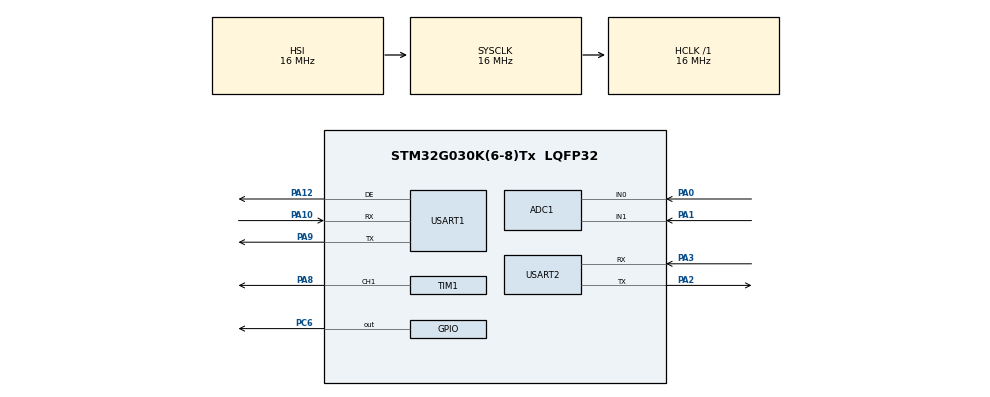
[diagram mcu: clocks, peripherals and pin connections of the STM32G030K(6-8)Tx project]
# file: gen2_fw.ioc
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ADC1.Channel-0\#ChannelRegularConversion=ADC_CHANNEL_0
ADC1.NbrOfConversionFlag=1
ADC1.Rank-0\#ChannelRegularConversion=1
ADC1.SamplingTime-0\#ChannelRegularConversion=ADC_SAMPLINGTIME_COMMON_1
ADC1.SelectedChannel=ADC_CHANNEL_0|ADC_CHANNEL_1
ADC1.master=1
Mcu.Family=STM32G0
Mcu.Name=STM32G030K(6-8)Tx
Mcu.Package=LQFP32
PA0.Mode=IN0
PA0.Signal=ADC1_IN0
PA1.Mode=IN1
PA1.Signal=ADC1_IN1
PA10.Mode=Asynchronous
PA10.Signal=USART1_RX
PA12\ [PA10].Mode=Hardware Flow Control (RS485)
PA12\ [PA10].Signal=USART1_DE
PA13.Mode=Serial_Wire
PA13.Signal=SYS_SWDIO
PA14-BOOT0.Mode=Serial_Wire
PA14-BOOT0.Signal=SYS_SWCLK
PA2.Mode=Asynchronous
PA2.Signal=USART2_TX
PA3.Mode=Asynchronous
PA3.Signal=USART2_RX
PA8.Signal=S_TIM1_CH1
PA9.Mode=Asynchronous
PA9.Signal=USART1_TX
PC14-OSC32_IN\ (PC14).Mode=HSE-External-Clock-Source
PC14-OSC32_IN\ (PC14).Signal=RCC_OSC_IN
PC6.Signal=GPIO_Output
ProjectManager.HeapSize=0x200
ProjectManager.StackSize=0x400
ProjectManager.TargetToolchain=CMake
RCC.AHBFreq_Value=16000000
RCC.CortexFreq_Value=16000000
RCC.EXTERNAL_CLOCK_VALUE=12288000
RCC.HCLKFreq_Value=16000000
RCC.HSE_VALUE=8000000
RCC.HSI_VALUE=16000000
RCC.LSE_VALUE=32768
RCC.SYSCLKFreq_VALUE=16000000
RCC.VCOOutputFreq_Value=128000000
SH.S_TIM1_CH1.0=TIM1_CH1,Output Compare1 CH1
TIM1.Channel-Output\ Compare1\ CH1=TIM_CHANNEL_1
USART1.VirtualMode-Asynchronous=VM_ASYNC
USART1.VirtualMode-Hardware\ Flow\ Control\ (RS485)=VM_ASYNC
USART2.VirtualMode-Asynchronous=VM_ASYNC
board=custom

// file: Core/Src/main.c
/* USER CODE BEGIN Header */
/**
 ******************************************************************************
 * @file           : main.c
 * @brief          : Main program body
 ******************************************************************************
 * @attention
 *
 * Copyright (c) 2026 STMicroelectronics.
 * All rights reserved.
 *
 * This software is licensed under terms that can be found in the LICENSE file
 * in the root directory of this software component.
 * If no LICENSE file comes with this software, it is provided AS-IS.
 *
 ******************************************************************************
 */
/* USER CODE END Header */
#include "main.h"

/* USER CODE BEGIN Includes */
#include "fifo.h"
#include "ir_adc.h"
#include "ir_processing.h"
#include "fsm.h"
#include "logger.h"
#include "message_types.h"
#include "rs485.h"
#include <stdlib.h>
/* USER CODE END Includes */

ADC_HandleTypeDef hadc1;

TIM_HandleTypeDef htim1;

UART_HandleTypeDef huart1;
UART_HandleTypeDef huart2;

void SystemClock_Config(void);
static void MX_GPIO_Init(void);
static void MX_ADC1_Init(void);
static void MX_TIM1_Init(void);
static void MX_USART1_UART_Init(void);
static void MX_USART2_UART_Init(void);

int main(void)
{

    /* MCU Configuration--------------------------------------------------------*/

    /* Reset of all peripherals, Initializes the Flash interface and the Systick. */
    HAL_Init();

    /* Configure the system clock */
    SystemClock_Config();

    /* Initialize all configured peripherals */
    MX_GPIO_Init();
    MX_ADC1_Init();
    MX_TIM1_Init();
    MX_USART1_UART_Init();
    MX_USART2_UART_Init();

    /* Infinite loop */
    while (1)
    {

    }
}

void SystemClock_Config(void)
{
    RCC_OscInitTypeDef RCC_OscInitStruct = {0};
    RCC_ClkInitTypeDef RCC_ClkInitStruct = {0};

    /** Configure the main internal regulator output voltage
     */
    HAL_PWREx_ControlVoltageScaling(PWR_REGULATOR_VOLTAGE_SCALE1);

    /** Initializes the RCC Oscillators according to the specified parameters
     * in the RCC_OscInitTypeDef structure.
     */
    RCC_OscInitStruct.OscillatorType = RCC_OSCILLATORTYPE_HSI;
    RCC_OscInitStruct.HSIState = RCC_HSI_ON;
    RCC_OscInitStruct.HSIDiv = RCC_HSI_DIV1;
    RCC_OscInitStruct.HSICalibrationValue = RCC_HSICALIBRATION_DEFAULT;
    RCC_OscInitStruct.PLL.PLLState = RCC_PLL_NONE;
    if (HAL_RCC_OscConfig(&RCC_OscInitStruct) != HAL_OK)
    {
        Error_Handler();
    }

    /** Initializes the CPU, AHB and APB buses clocks
     */
    RCC_ClkInitStruct.ClockType = RCC_CLOCKTYPE_HCLK | RCC_CLOCKTYPE_SYSCLK | RCC_CLOCKTYPE_PCLK1;
    RCC_ClkInitStruct.SYSCLKSource = RCC_SYSCLKSOURCE_HSI;
    RCC_ClkInitStruct.AHBCLKDivider = RCC_SYSCLK_DIV1;
    RCC_ClkInitStruct.APB1CLKDivider = RCC_HCLK_DIV1;

    if (HAL_RCC_ClockConfig(&RCC_ClkInitStruct, FLASH_LATENCY_0) != HAL_OK)
    {
        Error_Handler();
    }
}

static void MX_ADC1_Init(void)
{

    ADC_ChannelConfTypeDef sConfig = {0};

    /** Configure the global features of the ADC (Clock, Resolution, Data Alignment and number of
     * conversion)
     */
    hadc1.Instance = ADC1;
    hadc1.Init.ClockPrescaler = ADC_CLOCK_SYNC_PCLK_DIV2;
    hadc1.Init.Resolution = ADC_RESOLUTION_12B;
    hadc1.Init.DataAlign = ADC_DATAALIGN_RIGHT;
    hadc1.Init.ScanConvMode = ADC_SCAN_DISABLE;
    hadc1.Init.EOCSelection = ADC_EOC_SINGLE_CONV;
    hadc1.Init.LowPowerAutoWait = DISABLE;
    hadc1.Init.LowPowerAutoPowerOff = DISABLE;
    hadc1.Init.ContinuousConvMode = DISABLE;
    hadc1.Init.NbrOfConversion = 1;
    hadc1.Init.DiscontinuousConvMode = DISABLE;
    hadc1.Init.ExternalTrigConv = ADC_SOFTWARE_START;
    hadc1.Init.ExternalTrigConvEdge = ADC_EXTERNALTRIGCONVEDGE_NONE;
    hadc1.Init.DMAContinuousRequests = DISABLE;
    hadc1.Init.Overrun = ADC_OVR_DATA_PRESERVED;
    hadc1.Init.SamplingTimeCommon1 = ADC_SAMPLETIME_1CYCLE_5;
    hadc1.Init.SamplingTimeCommon2 = ADC_SAMPLETIME_1CYCLE_5;
    hadc1.Init.OversamplingMode = DISABLE;
    hadc1.Init.TriggerFrequencyMode = ADC_TRIGGER_FREQ_HIGH;
    if (HAL_ADC_Init(&hadc1) != HAL_OK)
    {
        Error_Handler();
    }

    /** Configure Regular Channel
     */
    sConfig.Channel = ADC_CHANNEL_0;
    sConfig.Rank = ADC_REGULAR_RANK_1;
    sConfig.SamplingTime = ADC_SAMPLINGTIME_COMMON_1;
    if (HAL_ADC_ConfigChannel(&hadc1, &sConfig) != HAL_OK)
    {
        Error_Handler();
    }
}

static void MX_TIM1_Init(void)
{

    TIM_MasterConfigTypeDef sMasterConfig = {0};
    TIM_OC_InitTypeDef sConfigOC = {0};
    TIM_BreakDeadTimeConfigTypeDef sBreakDeadTimeConfig = {0};

    htim1.Instance = TIM1;
    htim1.Init.Prescaler = 0;
    htim1.Init.CounterMode = TIM_COUNTERMODE_UP;
    htim1.Init.Period = 65535;
    htim1.Init.ClockDivision = TIM_CLOCKDIVISION_DIV1;
    htim1.Init.RepetitionCounter = 0;
    htim1.Init.AutoReloadPreload = TIM_AUTORELOAD_PRELOAD_DISABLE;
    if (HAL_TIM_OC_Init(&htim1) != HAL_OK)
    {
        Error_Handler();
    }
    sMasterConfig.MasterOutputTrigger = TIM_TRGO_RESET;
    sMasterConfig.MasterOutputTrigger2 = TIM_TRGO2_RESET;
    sMasterConfig.MasterSlaveMode = TIM_MASTERSLAVEMODE_DISABLE;
    if (HAL_TIMEx_MasterConfigSynchronization(&htim1, &sMasterConfig) != HAL_OK)
    {
        Error_Handler();
    }
    sConfigOC.OCMode = TIM_OCMODE_TIMING;
    sConfigOC.Pulse = 0;
    sConfigOC.OCPolarity = TIM_OCPOLARITY_HIGH;
    sConfigOC.OCNPolarity = TIM_OCNPOLARITY_HIGH;
    sConfigOC.OCFastMode = TIM_OCFAST_DISABLE;
    sConfigOC.OCIdleState = TIM_OCIDLESTATE_RESET;
    sConfigOC.OCNIdleState = TIM_OCNIDLESTATE_RESET;
    if (HAL_TIM_OC_ConfigChannel(&htim1, &sConfigOC, TIM_CHANNEL_1) != HAL_OK)
    {
        Error_Handler();
    }
    sBreakDeadTimeConfig.OffStateRunMode = TIM_OSSR_DISABLE;
    sBreakDeadTimeConfig.OffStateIDLEMode = TIM_OSSI_DISABLE;
    sBreakDeadTimeConfig.LockLevel = TIM_LOCKLEVEL_OFF;
    sBreakDeadTimeConfig.DeadTime = 0;
    sBreakDeadTimeConfig.BreakState = TIM_BREAK_DISABLE;
    sBreakDeadTimeConfig.BreakPolarity = TIM_BREAKPOLARITY_HIGH;
    sBreakDeadTimeConfig.BreakFilter = 0;
    sBreakDeadTimeConfig.BreakAFMode = TIM_BREAK_AFMODE_INPUT;
    sBreakDeadTimeConfig.Break2State = TIM_BREAK2_DISABLE;
    sBreakDeadTimeConfig.Break2Polarity = TIM_BREAK2POLARITY_HIGH;
    sBreakDeadTimeConfig.Break2Filter = 0;
    sBreakDeadTimeConfig.Break2AFMode = TIM_BREAK_AFMODE_INPUT;
    sBreakDeadTimeConfig.AutomaticOutput = TIM_AUTOMATICOUTPUT_DISABLE;
    if (HAL_TIMEx_ConfigBreakDeadTime(&htim1, &sBreakDeadTimeConfig) != HAL_OK)
    {
        Error_Handler();
    }
    HAL_TIM_MspPostInit(&htim1);
}

static void MX_USART1_UART_Init(void)
{

    huart1.Instance = USART1;
    huart1.Init.BaudRate = 115200;
    huart1.Init.WordLength = UART_WORDLENGTH_8B;
    huart1.Init.StopBits = UART_STOPBITS_1;
    huart1.Init.Parity = UART_PARITY_NONE;
    huart1.Init.Mode = UART_MODE_TX_RX;
    huart1.Init.HwFlowCtl = UART_HWCONTROL_NONE;
    huart1.Init.OverSampling = UART_OVERSAMPLING_16;
    huart1.Init.OneBitSampling = UART_ONE_BIT_SAMPLE_DISABLE;
    huart1.Init.ClockPrescaler = UART_PRESCALER_DIV1;
    huart1.AdvancedInit.AdvFeatureInit = UART_ADVFEATURE_NO_INIT;
    if (HAL_RS485Ex_Init(&huart1, UART_DE_POLARITY_HIGH, 0, 0) != HAL_OK)
    {
        Error_Handler();
    }
    if (HAL_UARTEx_SetTxFifoThreshold(&huart1, UART_TXFIFO_THRESHOLD_1_8) != HAL_OK)
    {
        Error_Handler();
    }
    if (HAL_UARTEx_SetRxFifoThreshold(&huart1, UART_RXFIFO_THRESHOLD_1_8) != HAL_OK)
    {
        Error_Handler();
    }
    if (HAL_UARTEx_DisableFifoMode(&huart1) != HAL_OK)
    {
        Error_Handler();
    }
}

static void MX_USART2_UART_Init(void)
{

    huart2.Instance = USART2;
    huart2.Init.BaudRate = 115200;
    huart2.Init.WordLength = UART_WORDLENGTH_8B;
    huart2.Init.StopBits = UART_STOPBITS_1;
    huart2.Init.Parity = UART_PARITY_NONE;
    huart2.Init.Mode = UART_MODE_TX_RX;
    huart2.Init.HwFlowCtl = UART_HWCONTROL_NONE;
    huart2.Init.OverSampling = UART_OVERSAMPLING_16;
    huart2.Init.OneBitSampling = UART_ONE_BIT_SAMPLE_DISABLE;
    huart2.Init.ClockPrescaler = UART_PRESCALER_DIV1;
    huart2.AdvancedInit.AdvFeatureInit = UART_ADVFEATURE_NO_INIT;
    if (HAL_UART_Init(&huart2) != HAL_OK)
    {
        Error_Handler();
    }
}

static void MX_GPIO_Init(void)
{
    GPIO_InitTypeDef GPIO_InitStruct = {0};

    /* GPIO Ports Clock Enable */
    __HAL_RCC_GPIOC_CLK_ENABLE();
    __HAL_RCC_GPIOA_CLK_ENABLE();

    /*Configure GPIO pin Output Level */
    HAL_GPIO_WritePin(GPIOC, GPIO_PIN_6, GPIO_PIN_RESET);

    /*Configure GPIO pin : PC6 */
    GPIO_InitStruct.Pin = GPIO_PIN_6;
    GPIO_InitStruct.Mode = GPIO_MODE_OUTPUT_PP;
    GPIO_InitStruct.Pull = GPIO_NOPULL;
    GPIO_InitStruct.Speed = GPIO_SPEED_FREQ_LOW;
    HAL_GPIO_Init(GPIOC, &GPIO_InitStruct);

}

void Error_Handler(void)
{
    __disable_irq();
    while (1)
    {
    }
}
